# MM32F3270 register map
File version: 3.01
CPU: CM3 r2p1, selectable endian, MPU, no FPU, 3 interrupt priority bits
Registers are 32-bit, read-write, reset 0x0 unless marked. A register's access mark holds for its fields unless they carry their own. Offsets are from the block's base; [hi:lo] are bit positions; 'fields as' and 'values as' point back to an identical list.

## I2C1 — Inter integrated circuit
Base 0x40005400
Same registers: I2C2 0x40005800
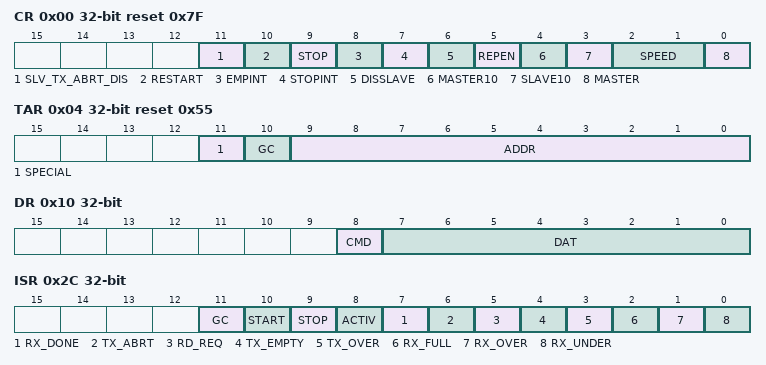
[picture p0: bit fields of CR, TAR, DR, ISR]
0x00 CR reset 0x7F — Control Register
  [11] SLV_TX_ABRT_DIS — when acting as a slave
  [10] RESTART — Whether to generate a RESTART signal after sending or receiving
  [9] STOP — Whether to generate a STOP signal after sending or receiving
  [8] EMPINT — This bit controls the generation of the TX_EMPTY interrupt
  [7] STOPINT — STOP_DET_IFADDRESSED
  [6] DISSLAVE — This bit controls whether I2C has its slave diabled
  [5] REPEN — Determines whether RESTART comdtions may be sent when acting as a master
  [4] MASTER10 — Address mode when acting as a master
  [3] SLAVE10 — When acting as a alsve
  [2:1] SPEED — These bits control at which speed the DW_apb_i2c operates
  [0] MASTER — This bit controls whether the DW_apb_i2c master is enabled
0x04 TAR reset 0x55 — Target Register
  [11] SPECIAL — This bit indicates whether software performs a General Call or START BYTE conmmend
  [10] GC — If bit 11(SPECIAL)is set to 1
  [9:0] ADDR — This is the target address for any master transaction
0x08 SAR reset 0x55 — Slave Address Register
  [9:0] ADDR — The SAR holds the slave address when the i2c is operation as a slave
0x10 DR — Data Command Register
  [8] CMD wo — This bit controls whether a read or a write is perormed
  [7:0] DAT — This register contains the data to be transimitted or received on the i2c bus.
0x14 SSHR reset 0x190 — SCL High Period Count for Std. Speed Register
  [15:0] CNT — This register sets the SCL clock high period count for standard speed
0x18 SSLR reset 0x1D6 — SCL Low Period Count for Std. Speed Register
  [15:0] CNT — This register sets the SCL clock low period count for standard speed
0x1C FSHR reset 0x3C — SCL High Period Count for Fast Speed Register
  [15:0] CNT — This register sets the SCL clock high_period count for standard speed
0x20 FSLR reset 0x82 — SCL Low Period Count for Fast Speed Register
  fields as SSLR
0x2C ISR ro — Interrupt Status Register
  [11] GC — General call
  [10] START — Start condition detection
  [9] STOP — Stop condition detection
  [8] ACTIV — This bit captures DW_spb_i2c acticity and stays set until it is cleared
  [7] RX_DONE — Transmit done
  [6] TX_ABRT — Transmit abort
  [5] RD_REQ — Read request
  [4] TX_EMPTY — Transmit buffer empty
  [3] TX_OVER — Transmit buffer over
  [2] RX_FULL — Receive buffer not empty
  [1] RX_OVER — Receive buffer over
  [0] RX_UNDER — Receive buffer under
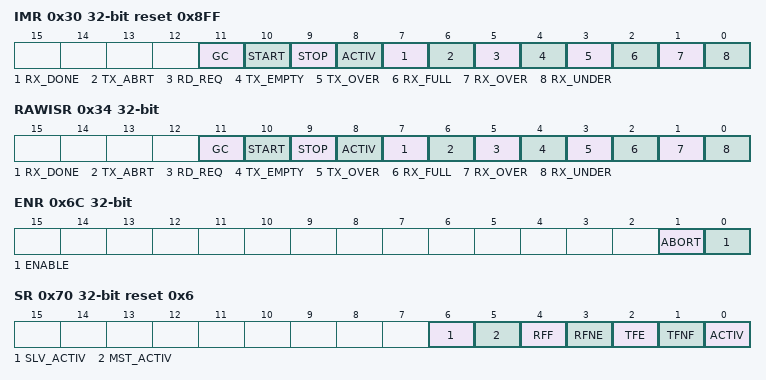
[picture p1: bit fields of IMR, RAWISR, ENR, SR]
0x30 IMR reset 0x8FF — Interrupt Mask Register
  fields as ISR
0x34 RAWISR ro — RAW Interrupt Status Register
  fields as ISR
0x38 RXTLR — Receive FIFO Threshold Level Register
  [7:0] TL — Receive FIFO threshold level
0x3C TXTLR — Transmit FIFO Threshold Level Register
  [7:0] TL — Transmit FIFO threshold level
0x40 ICR ro read-clears — Clear All Interrupt Register
  [0] ICR — Read this register to clear the combined interrupt
0x44 RX_UNDER ro read-clears — Clear RX_UNDER Interrupt Register
  [0] RX_UNDER — Read this register to clear the RX_UNDER interrupt(bit 0)of the RAWISR register
0x48 RX_OVER ro read-clears — Clear RX_OVER Interrupt Register
  [0] RX_OVER — Read this register to clear the RX_UNDER interrupt(bit 1)of the RAWISR register
0x4C TX_OVER ro read-clears — Clear TX_OVER Interrupt Register
  [0] TX_OVER — Read this register to clear the RX_UNDER interrupt(bit 3)of the RAWISR register
0x50 RD_REQ ro read-clears — Clear RD_REQ Interrupt Register
  [0] RD_REQ — Read this register to clear the RX_UNDER interrupt(bit 5)of the RAWISR register
0x54 TX_ABRT ro read-clears — Clear TX_ABRT Interrupt Register
  [0] TX_ABRT — Read this register to clear the RX_UNDER interrupt(bit 6)of the RAWISR register
0x58 RX_DONE ro read-clears — Clear RX_DONE Interrupt Register
  [0] RX_DONE — Read this register to clear the RX_UNDER interrupt(bit 7)of the RAWISR register
0x5C ACTIV ro read-clears — Clear ACTIVITY Interrupt Register
  [0] ACTIV — Reading this register clears the ACTIVITY interrupt if the I2C is not active anymore
0x60 STOP ro read-clears — Clear STOP_DET Interrupt Register
  [0] STOP — Read this register to clear the STOP_DET interrupt(bit 9)of the RAWISR register
0x64 START ro read-clears — Clear START_DET Interrupt Register
  [0] START — Read this register to clear the START_DET interrupt(bit 10)of the RAWISR register
0x68 GC ro read-clears — Clear GEN_CALL Interrupt Register
  [0] GC — Read this register to clear the GEN_CALL interrupt(bit 11)of the RAWISR register
0x6C ENR — Enable Register
  [1] ABORT — I2C transfer abort
  [0] ENABLE — I2C mode enable
0x70 SR ro reset 0x6 — Status Register
  [6] SLV_ACTIV — Slave FSM activity status
  [5] MST_ACTIV — Master FSM activity status
  [4] RFF — Receive FIFO completely full
  [3] RFNE — Receive FIFO not empty
  [2] TFE — Transmit FIFO completely empty
  [1] TFNF — Transmit FIFO not full
  [0] ACTIV — I2C activity status
0x74 TXFLR — Transmit FIFO Level Register
  [1:0] CNT — Transmit FIFO level.Contains the number of valid data entires in the transmit FIFO
0x78 RXFLR — Receive FIFO Level Register
  [1:0] CNT — Receive FIFO level. Contains the number of valid data entires in the receive FIFO
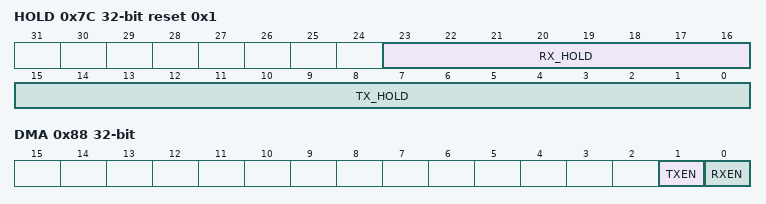
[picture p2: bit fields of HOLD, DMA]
0x7C HOLD reset 0x1 — SDA Hold Time Register
  [23:16] RX_HOLD — Sets the required SDA hold time in units of ic_clk period
  [15:0] TX_HOLD — Sets the required SDA hold time in units of ic_clk period
0x88 DMA — DMA Control Register
  [1] TXEN — Transmit DMA enable
  [0] RXEN — Receive DMA enable
0x94 SETUP reset 0x64 — SDA Setup Time Register
  [7:0] CNT — SDA setup
0x98 GCR reset 0x1 — ACK General Call Register
  [0] GC — ACK general call
0xB0 SLVMASK reset 0x3FF — Slave Address Mask Register
  [9:0] Mask — Slave Address Mask
0xB4 SLVRCVADDR ro — Receiver Address Register
  [9:0] ADDR — Slave Address
